# STM32WBA20xx register map
File version: 1.0
Registers are 32-bit, read-write, reset 0x0 unless marked. A register's access mark holds for its fields unless they carry their own. Offsets are from the block's base; [hi:lo] are bit positions.

## FLASH — FLASH Registers
Base 0x40022000
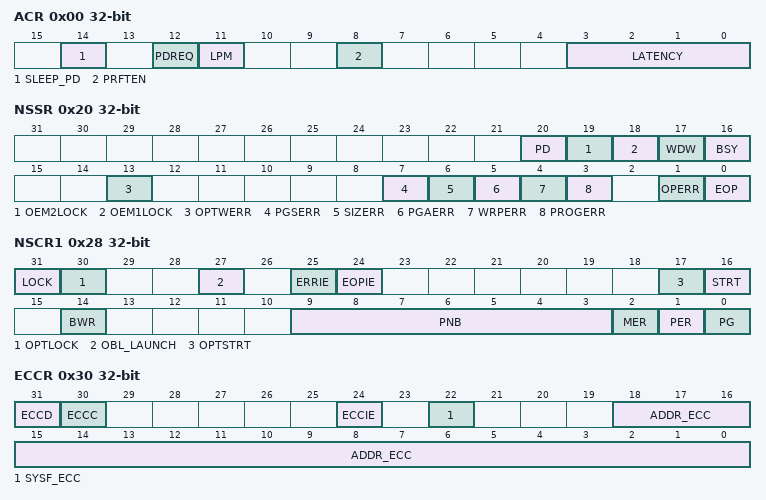
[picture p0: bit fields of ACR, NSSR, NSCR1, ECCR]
0x00 ACR — FLASH access control register
  [14] SLEEP_PD — Flash power-down mode during sleep
  [12] PDREQ — Flash power-down mode request
  [11] LPM — Low-Power read mode
  [8] PRFTEN — Prefetch enable
  [3:0] LATENCY
    0=FLASH Zero wait state; 1=FLASH One wait state; 2=FLASH Two wait states; 3=FLASH Three wait states; 4=FLASH Four wait states; 5=FLASH Five wait state; 6=FLASH Six wait state; 7=FLASH Seven wait states; 8=FLASH Eight wait states; 9=FLASH Nine wait states; 10=FLASH Ten wait state; 11=FLASH Eleven wait state; 12=FLASH Twelve wait states; 13=FLASH Thirteen wait states; 14=FLASH Fourteen wait states; 15=FLASH Fifteen wait states
0x08 NSKEYR — FLASH non-secure key register
  [31:0] NSKEY — Flash memory non-secure key
0x10 OPTKEYR — FLASH option key register
  [31:0] OPTKEY — Option byte key
0x18 PDKEYR — FLASH Bank power-down key register
  [31:0] PDKEY — Flash power-down key
0x20 NSSR — FLASH non-secure status register
  [20] PD — Flash in power-down mode
  [19] OEM2LOCK
  [18] OEM1LOCK
  [17] WDW — Non-secure wait data to write
  [16] BSY — Non-secure busy
  [13] OPTWERR — Option write error
  [7] PGSERR — Non-secure programming sequence error
  [6] SIZERR — Non-secure size error
  [5] PGAERR — Non-secure programming alignment error
  [4] WRPERR — Non-secure write protection error
  [3] PROGERR — Non-secure programming error
  [1] OPERR — Non-secure operation error
  [0] EOP — Non-secure end of operation
0x28 NSCR1 — FLASH non-secure control register
  [31] LOCK — Non-secure Lock
  [30] OPTLOCK — Option Lock
  [27] OBL_LAUNCH — Force the option byte loading
  [25] ERRIE — Non-secure error interrupt enable
  [24] EOPIE — Non-secure End of operation interrupt enable
  [17] OPTSTRT — Option Modification Start
  [16] STRT — Non-secure Start
  [14] BWR — Non-secure Burst Write Programming mode
  [9:3] PNB — Non-secure Page Number selection
  [2] MER — Non-secure Mass Erase
  [1] PER — Non-secure Page Erase
  [0] PG — Non-secure Programming
0x30 ECCR — FLASH ECC register
  [31] ECCD — ECC detection
  [30] ECCC — ECC correction
  [24] ECCIE — ECC correction interrupt enable
  [22] SYSF_ECC — System Flash ECC fail
  [18:0] ADDR_ECC — ECC fail address
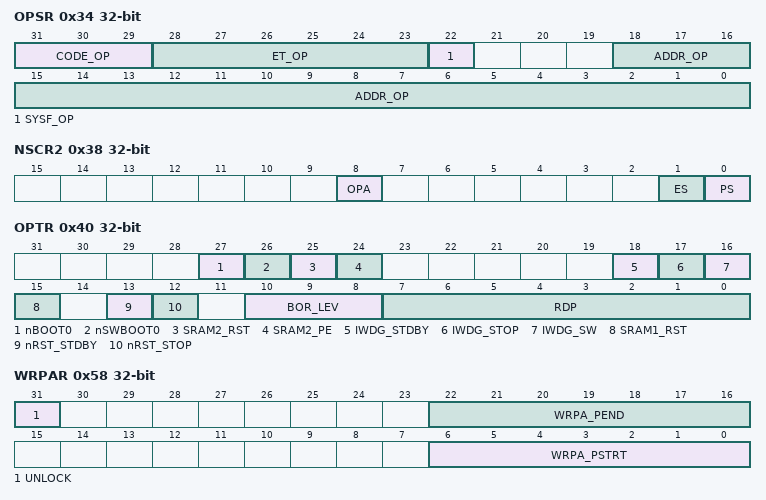
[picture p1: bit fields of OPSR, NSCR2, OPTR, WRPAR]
0x34 OPSR — FLASH OPSR register
  [31:29] CODE_OP — Flash memory operation code
  [28:23] ET_OP — Elapsed erase time before interruption
  [22] SYSF_OP — Operation in system Flash memory interrupted
  [18:0] ADDR_OP — Interrupted operation address
0x38 NSCR2 — FLASH non-secure control register
  [8] OPA — Flash operation abort
  [1] ES — Erase suspend request
  [0] PS — Program suspend request
0x40 OPTR — FLASH option control register
  [27] nBOOT0 — nBOOT0 option bit
  [26] nSWBOOT0 — Software BOOT0
  [25] SRAM2_RST — SRAM2 erase when system reset
  [24] SRAM2_PE — SRAM2 ECC detection and correction enable
  [18] IWDG_STDBY — Independent watchdog counter freeze in Standby mode
  [17] IWDG_STOP — Independent watchdog counter freeze in Stop mode
  [16] IWDG_SW — Independent watchdog selection
  [15] SRAM1_RST — SRAM1 erase upon system reset
  [13] nRST_STDBY
  [12] nRST_STOP
  [10:8] BOR_LEV — BOR reset Level
  [7:0] RDP — Readout protection level
0x44 NSBOOTADD0R — FLASH non-secure boot address 0 register
  [31:7] NSBOOTADD0 — Non-secure boot address 0
0x48 NSBOOTADD1R — FLASH non-secure boot address 1 register
  [31:7] NSBOOTADD1 — Non-secure boot address 1
0x58 WRPAR — FLASH WRP area A address register
  [31] UNLOCK — WPR first area A unlock
  [22:16] WRPA_PEND — WPR first area A end page
  [6:0] WRPA_PSTRT — WPR first area A start page
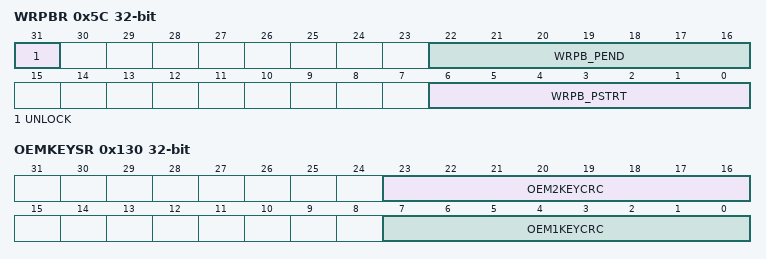
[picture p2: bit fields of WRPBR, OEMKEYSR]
0x5C WRPBR — FLASH WRP area B address register
  [31] UNLOCK — WPR first area B unlock
  [22:16] WRPB_PEND — WPR second area B end page
  [6:0] WRPB_PSTRT — WPR second area B start page
0x110 OEM1KEYR1 — FLASH OEM1 key register 1
  [31:0] OEM1KEY — OEM1 least significant bytes key
0x114 OEM1KEYR2 — FLASH OEM1 key register 2
  [31:0] OEM1KEY — OEM1 most significant bytes key
0x118 OEM1KEYR3 — FLASH OEM1 key register 3
  [31:0] OEM1KEY — OEM1KEY[31:0] bits (OEM1 key middle bytes)
0x11C OEM1KEYR4 — FLASH OEM1 key register 4
  [31:0] OEM1KEY — OEM1KEY[31:0] bits (OEM1 key most significant bytes)
0x120 OEM2KEYR1 — FLASH OEM2 key register 1
  [31:0] OEM2KEY — OEM2 least significant bytes key
0x124 OEM2KEYR2 — FLASH OEM2 key register 2
  [31:0] OEM2KEY — OEM2 most significant bytes key
0x128 OEM2KEYR3 — FLASH OEM2 key register 3
  [31:0] OEM2KEY — OEM2KEY[31:0] bits (OEM2 key middle bytes)
0x12C OEM2KEYR4 — FLASH OEM2 key register 4
  [31:0] OEM2KEY — OEM2KEY[31:0] bits (OEM2 key most significant bytes)
0x130 OEMKEYSR — FLASH OEM key status register
  [23:16] OEM2KEYCRC — OEM2KEYCRC[7:0] bits (OEM2 key CRC value)
  [7:0] OEM1KEYCRC — OEM1KEYCRC[7:0] bits (OEM1 key CRC value)
